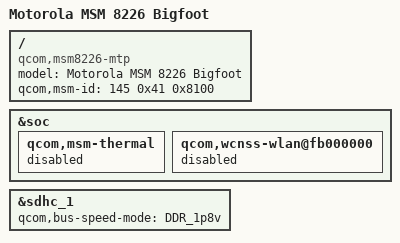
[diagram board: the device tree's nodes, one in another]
/* Copyright (c) 2014, The Linux Foundation. All rights reserved.
 *
 * This program is free software; you can redistribute it and/or modify
 * it under the terms of the GNU General Public License version 2 and
 * only version 2 as published by the Free Software Foundation.
 *
 * This program is distributed in the hope that it will be useful,
 * but WITHOUT ANY WARRANTY; without even the implied warranty of
 * MERCHANTABILITY or FITNESS FOR A PARTICULAR PURPOSE.  See the
 * GNU General Public License for more details.
 */

/dts-v1/;
#include "msm8226-v1.dtsi"
#include "msm8226-memory.dtsi"
#include "msm8226-qseecom.dtsi"
#include "msm8226-720p-mtp.dtsi"

/ {
	model = "Motorola MSM 8226 Bigfoot";
	compatible = "qcom,msm8226-mtp", "qcom,msm8226", "qcom,mtp";
	qcom,msm-id = <145 0x41 0x8100>;
};

&soc {
	qcom,msm-thermal {
		status = "disabled";
	};

	qcom,wcnss-wlan@fb000000 {
		status = "disabled";
	};
};

&sdhc_1 {
	qcom,bus-speed-mode = "DDR_1p8v";
};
